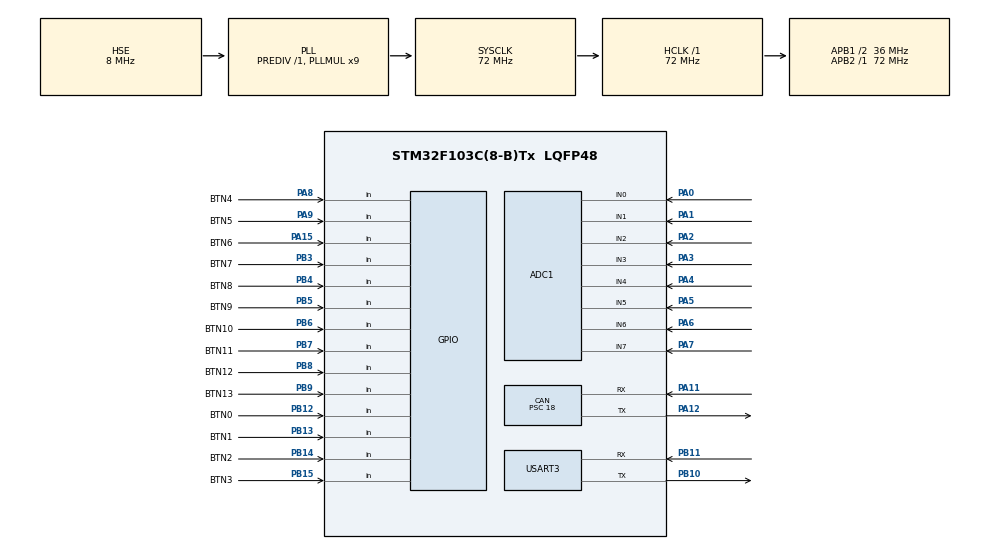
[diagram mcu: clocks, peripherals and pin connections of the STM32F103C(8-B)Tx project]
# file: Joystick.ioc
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ADC1.Channel-1\#ChannelRegularConversion=ADC_CHANNEL_0
ADC1.Channel-2\#ChannelRegularConversion=ADC_CHANNEL_1
ADC1.Channel-3\#ChannelRegularConversion=ADC_CHANNEL_2
ADC1.Channel-4\#ChannelRegularConversion=ADC_CHANNEL_3
ADC1.Channel-5\#ChannelRegularConversion=ADC_CHANNEL_4
ADC1.Channel-6\#ChannelRegularConversion=ADC_CHANNEL_5
ADC1.Channel-7\#ChannelRegularConversion=ADC_CHANNEL_6
ADC1.Channel-8\#ChannelRegularConversion=ADC_CHANNEL_7
ADC1.ExternalTrigConv=ADC_EXTERNALTRIGCONV_T3_TRGO
ADC1.NbrOfConversion=8
ADC1.NbrOfConversionFlag=1
ADC1.Rank-1\#ChannelRegularConversion=1
ADC1.Rank-2\#ChannelRegularConversion=2
ADC1.Rank-3\#ChannelRegularConversion=3
ADC1.Rank-4\#ChannelRegularConversion=4
ADC1.Rank-5\#ChannelRegularConversion=5
ADC1.Rank-6\#ChannelRegularConversion=6
ADC1.Rank-7\#ChannelRegularConversion=7
ADC1.Rank-8\#ChannelRegularConversion=8
ADC1.SamplingTime-1\#ChannelRegularConversion=ADC_SAMPLETIME_55CYCLES_5
ADC1.SamplingTime-2\#ChannelRegularConversion=ADC_SAMPLETIME_55CYCLES_5
ADC1.SamplingTime-3\#ChannelRegularConversion=ADC_SAMPLETIME_55CYCLES_5
ADC1.SamplingTime-4\#ChannelRegularConversion=ADC_SAMPLETIME_55CYCLES_5
ADC1.SamplingTime-5\#ChannelRegularConversion=ADC_SAMPLETIME_55CYCLES_5
ADC1.SamplingTime-6\#ChannelRegularConversion=ADC_SAMPLETIME_55CYCLES_5
ADC1.SamplingTime-7\#ChannelRegularConversion=ADC_SAMPLETIME_55CYCLES_5
ADC1.SamplingTime-8\#ChannelRegularConversion=ADC_SAMPLETIME_55CYCLES_5
ADC1.master=1
CAN.BS1=CAN_BS1_3TQ
CAN.BS2=CAN_BS2_4TQ
CAN.CalculateBaudRate=250000
CAN.CalculateTimeBit=4000
CAN.CalculateTimeQuantum=500.0
CAN.Prescaler=18
Dma.ADC1.0.Direction=DMA_PERIPH_TO_MEMORY
Dma.ADC1.0.Instance=DMA1_Channel1
Dma.ADC1.0.MemDataAlignment=DMA_MDATAALIGN_HALFWORD
Dma.ADC1.0.MemInc=DMA_MINC_ENABLE
Dma.ADC1.0.Mode=DMA_CIRCULAR
Dma.ADC1.0.PeriphDataAlignment=DMA_PDATAALIGN_HALFWORD
Dma.ADC1.0.PeriphInc=DMA_PINC_DISABLE
Dma.ADC1.0.Priority=DMA_PRIORITY_MEDIUM
Dma.Request0=ADC1
Mcu.Family=STM32F1
Mcu.Name=STM32F103C(8-B)Tx
Mcu.Package=LQFP48
NVIC.CAN1_SCE_IRQn=true\:0\:0\:false\:false\:true\:true\:true\:true
NVIC.DMA1_Channel1_IRQn=true\:0\:0\:false\:false\:true\:false\:true\:true
NVIC.PriorityGroup=NVIC_PRIORITYGROUP_4
PA0-WKUP.Signal=ADCx_IN0
PA1.Signal=ADCx_IN1
PA11.Mode=CAN_Activate
PA11.Signal=CAN_RX
PA12.Mode=CAN_Activate
PA12.Signal=CAN_TX
PA13.Mode=Serial_Wire
PA13.Signal=SYS_JTMS-SWDIO
PA14.Mode=Serial_Wire
PA14.Signal=SYS_JTCK-SWCLK
PA15.GPIO_Label=BTN6
PA15.GPIO_PuPd=GPIO_PULLUP
PA15.Signal=GPIO_Input
PA2.Signal=ADCx_IN2
PA3.Signal=ADCx_IN3
PA4.Signal=ADCx_IN4
PA5.Signal=ADCx_IN5
PA6.Signal=ADCx_IN6
PA7.Signal=ADCx_IN7
PA8.GPIO_Label=BTN4
PA8.GPIO_PuPd=GPIO_PULLUP
PA8.Signal=GPIO_Input
PA9.GPIO_Label=BTN5
PA9.GPIO_PuPd=GPIO_PULLUP
PA9.Signal=GPIO_Input
PB10.Mode=Asynchronous
PB10.Signal=USART3_TX
PB11.Mode=Asynchronous
PB11.Signal=USART3_RX
PB12.GPIO_Label=BTN0
PB12.GPIO_PuPd=GPIO_PULLUP
PB12.Signal=GPIO_Input
PB13.GPIO_Label=BTN1
PB13.GPIO_PuPd=GPIO_PULLUP
PB13.Signal=GPIO_Input
PB14.GPIO_Label=BTN2
PB14.GPIO_PuPd=GPIO_PULLUP
PB14.Signal=GPIO_Input
PB15.GPIO_Label=BTN3
PB15.GPIO_PuPd=GPIO_PULLUP
PB15.Signal=GPIO_Input
PB3.GPIO_Label=BTN7
PB3.GPIO_PuPd=GPIO_PULLUP
PB3.Signal=GPIO_Input
PB4.GPIO_Label=BTN8
PB4.GPIO_PuPd=GPIO_PULLUP
PB4.Signal=GPIO_Input
PB5.GPIO_Label=BTN9
PB5.GPIO_PuPd=GPIO_PULLUP
PB5.Signal=GPIO_Input
PB6.GPIO_Label=BTN10
PB6.GPIO_PuPd=GPIO_PULLUP
PB6.Signal=GPIO_Input
PB7.GPIO_Label=BTN11
PB7.GPIO_PuPd=GPIO_PULLUP
PB7.Signal=GPIO_Input
PB8.GPIO_Label=BTN12
PB8.GPIO_PuPd=GPIO_PULLUP
PB8.Signal=GPIO_Input
PB9.GPIO_Label=BTN13
PB9.GPIO_PuPd=GPIO_PULLUP
PB9.Signal=GPIO_Input
PD0-OSC_IN.Mode=HSE-External-Oscillator
PD0-OSC_IN.Signal=RCC_OSC_IN
PD1-OSC_OUT.Mode=HSE-External-Oscillator
PD1-OSC_OUT.Signal=RCC_OSC_OUT
ProjectManager.HeapSize=0x200
ProjectManager.StackSize=0x400
ProjectManager.TargetToolchain=MDK-ARM V5
RCC.ADCPresc=RCC_ADCPCLK2_DIV6
RCC.AHBFreq_Value=72000000
RCC.APB1CLKDivider=RCC_HCLK_DIV2
RCC.APB1Freq_Value=36000000
RCC.APB1TimFreq_Value=72000000
RCC.APB2Freq_Value=72000000
RCC.APB2TimFreq_Value=72000000
RCC.HCLKFreq_Value=72000000
RCC.PLLMUL=RCC_PLL_MUL9
RCC.PLLSourceVirtual=RCC_PLLSOURCE_HSE
RCC.SYSCLKFreq_VALUE=72000000
RCC.SYSCLKSource=RCC_SYSCLKSOURCE_PLLCLK
RCC.USBFreq_Value=72000000
SH.ADCx_IN0.0=ADC1_IN0,IN0
SH.ADCx_IN1.0=ADC1_IN1,IN1
SH.ADCx_IN2.0=ADC1_IN2,IN2
SH.ADCx_IN3.0=ADC1_IN3,IN3
SH.ADCx_IN4.0=ADC1_IN4,IN4
SH.ADCx_IN5.0=ADC1_IN5,IN5
SH.ADCx_IN6.0=ADC1_IN6,IN6
SH.ADCx_IN7.0=ADC1_IN7,IN7
TIM3.Period=1000
TIM3.Prescaler=48
TIM3.TIM_MasterOutputTrigger=TIM_TRGO_UPDATE
USART3.VirtualMode=VM_ASYNC
VP_TIM3_VS_ClockSourceINT.Mode=Internal
board=custom

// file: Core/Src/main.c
/* USER CODE BEGIN Header */
/**
  ******************************************************************************
  * @file           : main.c
  * @brief          : Main program body
  ******************************************************************************
  * @attention
  *
  * Copyright (c) 2024 STMicroelectronics.
  * All rights reserved.
  *
  * This software is licensed under terms that can be found in the LICENSE file
  * in the root directory of this software component.
  * If no LICENSE file comes with this software, it is provided AS-IS.
  *
  ******************************************************************************
  */
/* USER CODE END Header */
#include "main.h"
#include "adc.h"
#include "can.h"
#include "dma.h"
#include "tim.h"
#include "usart.h"
#include "gpio.h"

/* USER CODE BEGIN Includes */

#include "joystick.h"

/* USER CODE END Includes */

void SystemClock_Config(void);

int main(void)
{

  /* MCU Configuration--------------------------------------------------------*/

  /* Reset of all peripherals, Initializes the Flash interface and the Systick. */
  HAL_Init();

  /* Configure the system clock */
  SystemClock_Config();

  /* Initialize all configured peripherals */
  MX_GPIO_Init();
  MX_DMA_Init();
  MX_ADC1_Init();
  MX_TIM3_Init();
  MX_CAN_Init();
  MX_USART3_UART_Init();
  /* USER CODE BEGIN 2 */

  JS_Init();

  HAL_ADCEx_Calibration_Start(&hadc1);
  if (HAL_TIM_Base_Start_IT(&htim3) != HAL_OK)
  {
    Error_Handler();
  }
  if (HAL_ADC_Start_DMA(&hadc1, (uint32_t *)&ADC_Data[0], 8) != HAL_OK)
  {
    Error_Handler();
  }

	HAL_CAN_ActivateNotification(&hcan, CAN_IT_ERROR);
  HAL_CAN_Start(&hcan);

  /* USER CODE END 2 */

  /* Infinite loop */
  while (1)
  {

    /* USER CODE BEGIN 3 */

    if (ADC1_Data_Ready != 0)
    {
      JS_Update();
      JS_Transmit();

      ADC1_Data_Ready = 0;

      // /* Print the value of 8 sticks */
      // for (uint8_t i = 0; i < 8; i++)
      // {
      //   printf("%d ", report_data[i]);
      // }
      // printf("\r\n");

      // /* Print the value of 14 buttons */
      // for (int8_t bit = 15; bit >= 0; bit--)
      // {
      //   if (report_data[8] & (1 << bit))
      //   {
      //     printf("1");
      //   }
      //   else
      //   {
      //     printf("0");
      //   }
      // }
      // printf("\r\n");
    }
    HAL_Delay(5);
  }
  /* USER CODE END 3 */
}

void SystemClock_Config(void)
{
  RCC_OscInitTypeDef RCC_OscInitStruct = {0};
  RCC_ClkInitTypeDef RCC_ClkInitStruct = {0};
  RCC_PeriphCLKInitTypeDef PeriphClkInit = {0};

  /** Initializes the RCC Oscillators according to the specified parameters
  * in the RCC_OscInitTypeDef structure.
  */
  RCC_OscInitStruct.OscillatorType = RCC_OSCILLATORTYPE_HSE;
  RCC_OscInitStruct.HSEState = RCC_HSE_ON;
  RCC_OscInitStruct.HSEPredivValue = RCC_HSE_PREDIV_DIV1;
  RCC_OscInitStruct.HSIState = RCC_HSI_ON;
  RCC_OscInitStruct.PLL.PLLState = RCC_PLL_ON;
  RCC_OscInitStruct.PLL.PLLSource = RCC_PLLSOURCE_HSE;
  RCC_OscInitStruct.PLL.PLLMUL = RCC_PLL_MUL9;
  if (HAL_RCC_OscConfig(&RCC_OscInitStruct) != HAL_OK)
  {
    Error_Handler();
  }

  /** Initializes the CPU, AHB and APB buses clocks
  */
  RCC_ClkInitStruct.ClockType = RCC_CLOCKTYPE_HCLK|RCC_CLOCKTYPE_SYSCLK
                              |RCC_CLOCKTYPE_PCLK1|RCC_CLOCKTYPE_PCLK2;
  RCC_ClkInitStruct.SYSCLKSource = RCC_SYSCLKSOURCE_PLLCLK;
  RCC_ClkInitStruct.AHBCLKDivider = RCC_SYSCLK_DIV1;
  RCC_ClkInitStruct.APB1CLKDivider = RCC_HCLK_DIV2;
  RCC_ClkInitStruct.APB2CLKDivider = RCC_HCLK_DIV1;

  if (HAL_RCC_ClockConfig(&RCC_ClkInitStruct, FLASH_LATENCY_2) != HAL_OK)
  {
    Error_Handler();
  }
  PeriphClkInit.PeriphClockSelection = RCC_PERIPHCLK_ADC;
  PeriphClkInit.AdcClockSelection = RCC_ADCPCLK2_DIV6;
  if (HAL_RCCEx_PeriphCLKConfig(&PeriphClkInit) != HAL_OK)
  {
    Error_Handler();
  }
}

void Error_Handler(void)
{
  __disable_irq();
  while (1)
  {
  }
}
